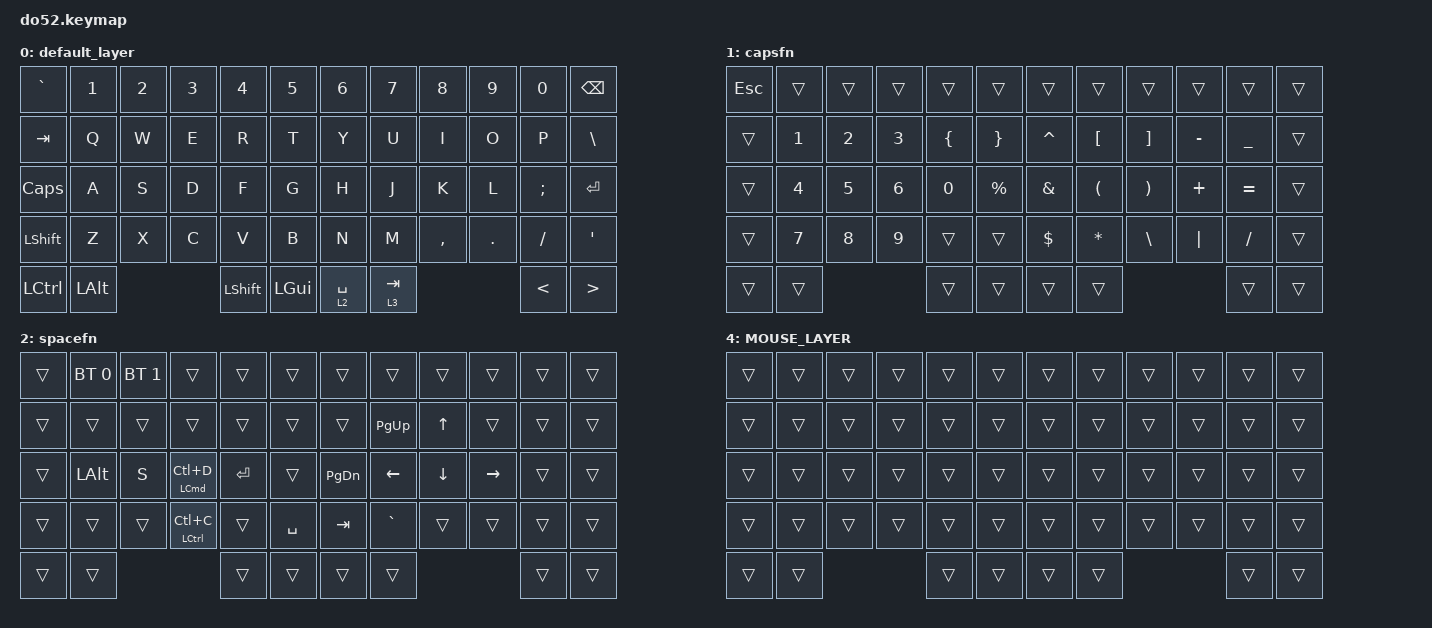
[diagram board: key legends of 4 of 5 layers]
#include <dt-bindings/zmk/mouse.h>
#include <behaviors.dtsi>
#include <dt-bindings/zmk/bt.h>
#include <dt-bindings/zmk/keys.h>
#include <dt-bindings/zmk/pointing.h>

/ {
    joystick_listener {
        compatible = "zmk,input-listener";
        device = <&joystick_split>;

        scroll {
            compatible = "zmk,behavior-mapper"; 
            layers = <4>;
            input-processors = <&zip_xy_to_scroll_mapper>;
        };
    };

    behaviors {
        fn: fn {
            compatible = "zmk,behavior-hold-tap";
            label = "FN";
            bindings = <&mo>, <&kp>;

            #binding-cells = <2>;
            tapping-term-ms = <50>;
            hold-trigger-key-positions = <52 53>;
        };

        to_if_hold: to_if_hold {
            compatible = "zmk,behavior-hold-tap";
            label = "TO_IF_HOLD";
            bindings = <&kp>, <&kp>;

            #binding-cells = <2>;
            tapping-term-ms = <50>;
        };
    };

    combos {
        compatible = "zmk,combos";

        left_mouse_click {
            bindings = <&mkp MB1>;
            key-positions = <27 28>;
        };

        mouse_right_click {
            bindings = <&mkp MB2>;
            key-positions = <31 32>;
        };

        mouse_back {
            bindings = <&mkp MB4>;
            key-positions = <39 40>;
        };

        mouse_forward {
            bindings = <&mkp MB5>;
            key-positions = <42 43>;
        };
    };

    keymap {
        compatible = "zmk,keymap";

        default_layer {
            // ---------------------------------------------------------------------------------
            // |   `  |  1  |  2  |  3  |  4  |  5  |     |  6  |  7  |  8  |  9  |  0  | BKSP |
            // |  TAB |  Q  |  W  |  E  |  R  |  T  |     |  Y  |  U  |  I  |  O  |  P  |  \   |
            // | CAPS |  A  |  S  |  D  |  F  |  G  |     |  H  |  J  |  K  |  L  |  ;  |  ENT |
            // | SHFT |  Z  |  X  |  C  |  V  |  B  |     |  N  |  M  |  ,  |  .  |  /  | APOS |
            // | CTRL | ALT | GUI | SPC | SPC | SPC |     | SPC | LOW |LARW |DARW |UARW | RARW |

            bindings = <
&kp GRAVE  &kp N1    &kp N2  &kp N3  &kp N4          &kp N5      &kp N6       &kp N7     &kp N8     &kp N9   &kp N0         &kp BSPC
&kp TAB    &kp Q     &kp W   &kp E   &kp R           &kp T       &kp Y        &kp U      &kp I      &kp O    &kp P          &kp BSLH
&kp CAPS   &kp A     &kp S   &kp D   &kp F           &kp G       &kp H        &kp J      &kp K      &kp L    &kp SEMI       &kp RET
&kp LSHFT  &kp Z     &kp X   &kp C   &kp V           &kp B       &kp N        &kp M      &kp COMMA  &kp DOT  &kp FSLH       &kp APOS
&kp LCTRL  &kp LALT                  &kp LEFT_SHIFT  &kp LGUI    &fn 2 SPACE  &fn 3 TAB                      &kp LESS_THAN  &kp GREATER_THAN
            >;
        };

        capsfn {
            bindings = <
&kp ESC  &trans  &trans  &trans  &trans          &trans             &trans         &trans                &trans                 &trans     &trans          &trans
&trans   &kp N1  &kp N2  &kp N3  &kp LEFT_BRACE  &kp RIGHT_BRACE    &kp CARET      &kp LEFT_BRACKET      &kp RIGHT_BRACKET      &kp MINUS  &kp UNDERSCORE  &trans
&trans   &kp N4  &kp N5  &kp N6  &kp N0          &kp PERCENT        &kp AMPERSAND  &kp LEFT_PARENTHESIS  &kp RIGHT_PARENTHESIS  &kp PLUS   &kp EQUAL       &trans
&trans   &kp N7  &kp N8  &kp N9  &trans          &trans             &kp DOLLAR     &kp ASTERISK          &kp BACKSLASH          &kp PIPE   &kp SLASH       &trans
&trans   &trans                  &trans          &trans             &trans         &trans                                                  &trans          &trans
            >;
        };

        spacefn {
            bindings = <
&trans  &bt BT_SEL 0  &bt BT_SEL 1  &trans                          &trans   &trans       &trans     &trans     &trans    &trans     &trans  &trans
&trans  &trans        &trans        &trans                          &trans   &trans       &trans     &kp PG_UP  &kp UP    &trans     &trans  &trans
&trans  &kp LEFT_ALT  &kp S         &to_if_hold LEFT_COMMAND LC(D)  &kp RET  &trans       &kp PG_DN  &kp LEFT   &kp DOWN  &kp RIGHT  &trans  &trans
&trans  &trans        &trans        &to_if_hold LEFT_CONTROL LC(C)  &trans   &kp SPACE    &kp TAB    &kp GRAVE  &trans    &trans     &trans  &trans
&trans  &trans                                                      &trans   &trans       &trans     &trans                          &trans  &trans
            >;
        };

        lower_layer {
            // ------------------------------------------------------------------------------------------------------------
            // |       |  BT1  |  BT2  |  BT3  |  BT4  |  BT5  |          |       |       |       |       |       | BTCLR |
            // |       |       |       |       |       |       |          |       |       |       |       |       |       |
            // |       |       |       | LPAR  | RPAR  |       |          |       | LBKT  | RBKT  |       |       |       |
            // |       |       |       |       |       |       |          |       |       |       |       |       |       |

            bindings = <
&trans  &bt BT_SEL 0  &bt BT_SEL 1  &bt BT_SEL 2  &bt BT_SEL 3  &bt BT_SEL 4    &trans  &trans    &trans    &trans     &trans     &bt BT_CLR
&trans  &trans        &trans        &trans        &trans        &trans          &trans  &trans    &trans    &trans     &trans     &trans
&trans  &trans        &trans        &kp LPAR      &kp RPAR      &trans          &trans  &kp LBKT  &kp RBKT  &kp MINUS  &kp EQUAL  &trans
&trans  &trans        &trans        &trans        &trans        &trans          &trans  &trans
            >;
        };

        MOUSE_LAYER {
            bindings = <
&trans  &trans  &trans  &trans  &trans  &trans    &trans  &trans  &trans  &trans  &trans  &trans
&trans  &trans  &trans  &trans  &trans  &trans    &trans  &trans  &trans  &trans  &trans  &trans
&trans  &trans  &trans  &trans  &trans  &trans    &trans  &trans  &trans  &trans  &trans  &trans
&trans  &trans  &trans  &trans  &trans  &trans    &trans  &trans  &trans  &trans  &trans  &trans
&trans  &trans                  &trans  &trans    &trans  &trans                  &trans  &trans
            >;
        };
    };
};
